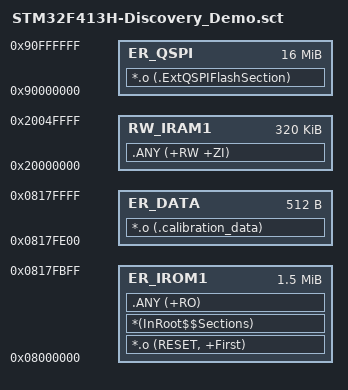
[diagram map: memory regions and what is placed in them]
; *************************************************************
; *** Scatter-Loading Description File generated by uVision ***
; *************************************************************

LR_IROM1 0x08000000 0x0017FC00  {    ; load region size_region
  ER_IROM1 0x08000000 0x0017FC00  {  ; load address = execution address
   *.o (RESET, +First)
   *(InRoot$$Sections)
   .ANY (+RO)
  }
  RW_IRAM1 0x20000000 0x00050000  {  ; RW data
   .ANY (+RW +ZI)
  }
}
LR_QSPI 0x90000000 0x1000000 {
ER_QSPI 0x90000000 0x1000000 {
*.o (.ExtQSPIFlashSection)
}
}
LR_DATA 0x0817FE00 0x200 {
  ER_DATA 0x0817FE00 0x200 { 
  *.o (.calibration_data) 
  }
  }
    
